# CY8C5888LTI_LP097 register map
File version: 0.1
CY8C58LP
Registers are 8-bit, read-write, no defined reset value unless marked. A register's access mark holds for its fields unless they carry their own. Offsets are from the block's base; lines under a group give offsets from that group; [hi:lo] are bit positions; {n}, {i} and the like mark numbered series; 'fields as' and 'values as' point back to an identical list; <NAME> marks a mode.

## Memory map
0x00000000 ADC
0x00000000 COUNTER_ENC
0x00000000 LED_GREEN_CTRL
0x00000000 ADC_N_CHANNELS_USED
0x00000000 MOTOR_ON_OFF_1
0x00000000 ADC_STATUS
0x00000000 ADC_SOC
0x00000000 MOTOR_ON_OFF_2
0x00000000 UART_BT — UART
0x00000000 RESET_COUNTERS
0x00000000 MOTOR_DRIVER_TYPE
0x00000000 Chip_Select_ENCODER_LINE
0x00000000 MOTOR_DIR_1
0x00000000 Chip_Select_IMU
0x00000000 PWM_MOTORS
0x00000000 PACER_TIMER
0x00000000 LED_RED_CTRL
0x00000000 MOTOR_DIR_2
0x00000000 MY_TIMER
0x00000000 UART_RS485 — UART
0x00000000 FF_STATUS
0x00000000 RESET_FF
0x00000000 CYCLES_TIMER

## COUNTER_ENC
Base 0x00000000
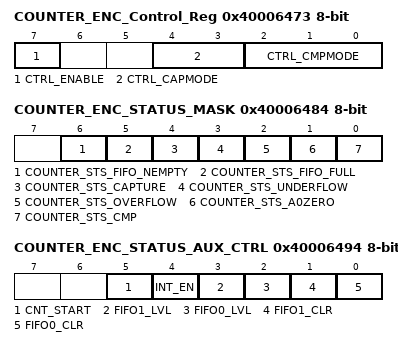
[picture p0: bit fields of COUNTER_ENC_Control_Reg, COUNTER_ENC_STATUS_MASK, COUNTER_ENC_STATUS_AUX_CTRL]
0x40006473 COUNTER_ENC_Control_Reg — UDB Control Register - Assigned Control Register Value
  [7] CTRL_ENABLE — Enable Counter
  [4:3] CTRL_CAPMODE — Capture mode
  [2:0] CTRL_CMPMODE — Compare mode
0x40006484 COUNTER_ENC_STATUS_MASK — UDB Status bits Interrupt Mask Enable Register
  [6] COUNTER_STS_FIFO_NEMPTY — FIFO Not Empty Status
  [5] COUNTER_STS_FIFO_FULL — FIFO Full Status
  [4] COUNTER_STS_CAPTURE — Capture Status
  [3] COUNTER_STS_UNDERFLOW — Underflow status
  [2] COUNTER_STS_OVERFLOW — Overflow status
  [1] COUNTER_STS_A0ZERO — A0 Zero ouput status
  [0] COUNTER_STS_CMP — Compare output status
0x40006494 COUNTER_ENC_STATUS_AUX_CTRL — UDB Auxilliary Control Register
  [5] CNT_START — FIFO0 clear
    0=E_CNT_START0 (Disable counter); 1=E_CNT_START1 (Enable counter)
  [4] INT_EN
    0=E_INT_EN0 (Interrupt disabled); 1=E_INT_EN1 (Interrupt enabled)
  [3] FIFO1_LVL — FIFO level
    0=E_FIFO_LVL_0 (FIFO LVL: input mode: FIFO not full; output mode: FIFO not empty); 1=E_FIFO_LVL_1 (FIFO LVL: input mode: FIFO at least 1/2 empty; output mode: FIFO at least 1/2 full)
  [2] FIFO0_LVL — FIFO level
    values as FIFO1_LVL
  [1] FIFO1_CLR — FIFO1 clear
    0=E_FIFO_CLR_0 (Normal FIFO operation); 1=E_FIFO_CLR_1 (Clear FIFO state)
  [0] FIFO0_CLR — FIFO0 clear
    values as FIFO1_CLR
0x40006507 COUNTER_ENC_COUNTER — UDB.A0 - Current Counter Value
0x40006527 COUNTER_ENC_PERIOD — UDB.D0 - Assigned Period
0x40006537 COUNTER_ENC_COMPARE — UDB.D1 - Assigned Compare Value

## LED_GREEN_CTRL
Base 0x00000000
0x40006575 LED_GREEN_CTRL_CONTROL_REG

## ADC_N_CHANNELS_USED
Base 0x00000000
0x40006577 ADC_N_CHANNELS_USED_CONTROL_REG

## MOTOR_ON_OFF_1
Base 0x00000000
0x40006474 MOTOR_ON_OFF_1_CONTROL_REG

## ADC_STATUS
Base 0x00000000
0x4000646E ADC_STATUS_STATUS_REG
0x4000648E ADC_STATUS_MASK_REG
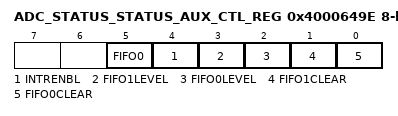
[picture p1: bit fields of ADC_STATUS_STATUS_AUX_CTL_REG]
0x4000649E ADC_STATUS_STATUS_AUX_CTL_REG
  [5] FIFO0 — FIFO0 clear
    1=ENABLED (Enable counter); 0=DISABLED (Disable counter)
  [4] INTRENBL — Enables or disables the Interrupt
    1=ENABLED (Interrupt enabled); 0=DISABLED (Interrupt disabled)
  [3] FIFO1LEVEL — FIFO level
    1=ENABLED (FIFO LVL: input mode: FIFO at least 1/2 empty; output mode: FIFO at least 1/2 full); 0=DISABLED (FIFO LVL: input mode: FIFO not full; output mode: FIFO not empty)
  [2] FIFO0LEVEL — FIFO level
    values as FIFO1LEVEL
  [1] FIFO1CLEAR — FIFO clear
    1=ENABLED (Clear FIFO state); 0=DISABLED (Normal FIFO operation)
  [0] FIFO0CLEAR — FIFO clear
    values as FIFO1CLEAR

## ADC_SOC
Base 0x00000000
0x40006578 ADC_SOC_CONTROL_REG

## MOTOR_ON_OFF_2
Base 0x00000000
0x4000657A MOTOR_ON_OFF_2_CONTROL_REG

## UART_BT — UART
Base 0x00000000
0x40006420 RX_UART_BT_RX_ADDRESS1 — RX Address1 Register
0x40006430 RX_UART_BT_RX_ADDRESS2 — RX Address2 Register
0x40006440 RX_UART_BT_RX_DATA — RX Data Register
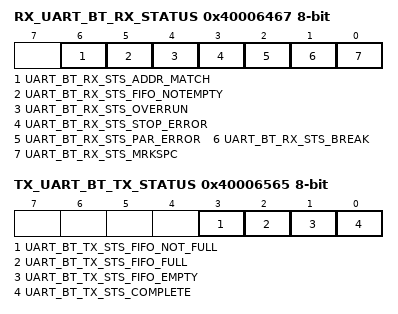
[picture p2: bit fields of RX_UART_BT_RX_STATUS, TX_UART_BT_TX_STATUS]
0x40006467 RX_UART_BT_RX_STATUS — RX status register
  [6] UART_BT_RX_STS_ADDR_MATCH ro, [5] UART_BT_RX_STS_FIFO_NOTEMPTY ro, [4] UART_BT_RX_STS_OVERRUN ro, [3] UART_BT_RX_STS_STOP_ERROR ro, [2] UART_BT_RX_STS_PAR_ERROR ro, [1] UART_BT_RX_STS_BREAK ro, [0] UART_BT_RX_STS_MRKSPC ro
0x40006545 TX_UART_BT_TX_DATA — TX Data Register
0x40006565 TX_UART_BT_TX_STATUS — TX status register
  [3] UART_BT_TX_STS_FIFO_NOT_FULL ro, [2] UART_BT_TX_STS_FIFO_FULL ro, [1] UART_BT_TX_STS_FIFO_EMPTY ro, [0] UART_BT_TX_STS_COMPLETE ro
